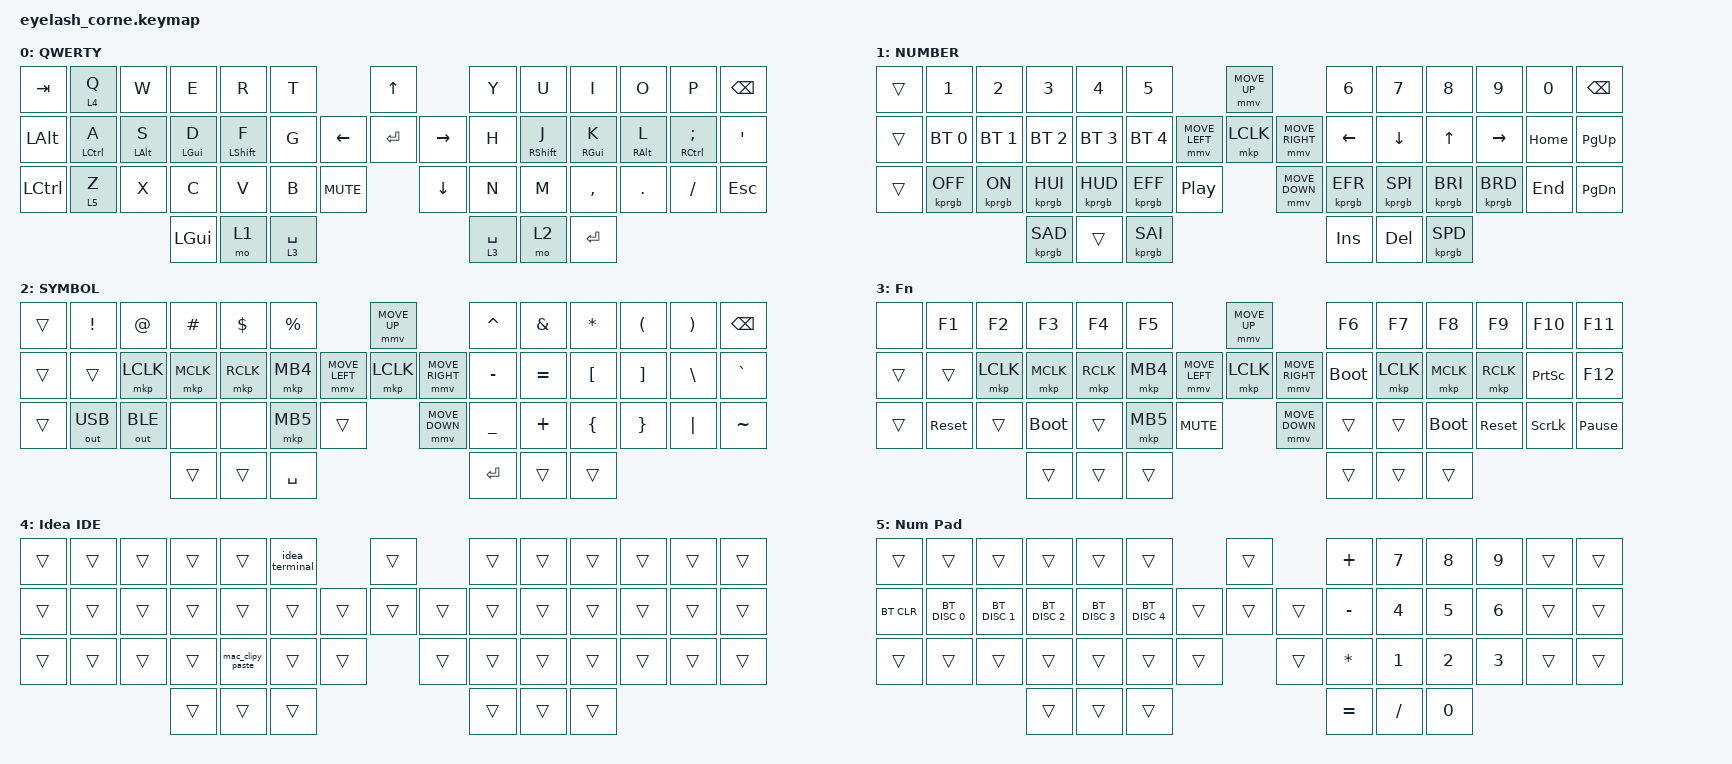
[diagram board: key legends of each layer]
#define ZMK_POINTING_DEFAULT_MOVE_VAL 1200  // 600
#define ZMK_POINTING_DEFAULT_SCRL_VAL 25   // 10

#include <input/processors.dtsi>
#include <zephyr/dt-bindings/input/input-event-codes.h>
#include <behaviors.dtsi>
#include <behaviors/runtime-sensor-rotate.dtsi>
#include <dt-bindings/zmk/bt.h>
#include <dt-bindings/zmk/keys.h>
#include <dt-bindings/zmk/outputs.h>
#include <dt-bindings/zmk/pointing.h>
#include <dt-bindings/zmk/rgb.h>

&soft_off { hold-time-ms = <2000>; };

/ {
    behaviors {
        td0: td0 {
            compatible = "zmk,behavior-tap-dance";
            display-name = "Shift/Caps Lock Tap Dance";
            #binding-cells = <0>;
            bindings = <&kp LEFT_SHIFT>, <&kp CAPS>;
        };

        rsr_vol: rsr_vol {
            compatible = "zmk,behavior-runtime-sensor-rotate";
            #sensor-binding-cells = <0>;
            tap-ms = <5>;
            cw-binding = <&kp C_VOL_UP>;
            ccw-binding = <&kp C_VOL_DN>;
        };

        rsr_trans: rsr_trans {
            compatible = "zmk,behavior-runtime-sensor-rotate";
            #sensor-binding-cells = <0>;
            tap-ms = <0>;
        };

        kprgb: kprgb {
            compatible = "keypaw,behavior-rgb-matrix";
            #binding-cells = <2>;
            initial-effect = <0>;
            // Must be set: the module reads an absent boolean as false (off)
            initial-on;

            // QWERTY stays dark; the layer overlays below do the lighting
            fx_off: fx_off {
                compatible = "keypaw,rgb-matrix-solid";
                #binding-cells = <0>;
                color = <0x000000>;
            };
        };

        hrm_left: hrm_left {
            compatible = "zmk,behavior-hold-tap";
            label = "HRM_LEFT";
            bindings = <&kp>, <&kp>;

            #binding-cells = <2>;
            tapping-term-ms = <150>;
            quick-tap-ms = <140>;
            hold-trigger-key-positions = <1 0 13 28 29 14 15 2 3 4 5 18 33 44 43 42 32 17 16 31 30>;
            hold-trigger-on-release;
            flavor = "tap-preferred";
        };

        hrm_right: hrm_right {
            compatible = "zmk,behavior-hold-tap";
            label = "HRM_RIGHT";
            bindings = <&kp>, <&kp>;

            #binding-cells = <2>;
            hold-trigger-key-positions = <7 8 9 10 11 12 22 23 24 25 26 27 36 37 38 39 40 41 45 46 47>;
            tapping-term-ms = <150>;
            quick-tap-ms = <140>;
            hold-trigger-on-release;
            flavor = "tap-preferred";
        };
    };

    macros {
        lock_mac: lock_mac {
            compatible = "zmk,behavior-macro";
            #binding-cells = <0>;
            bindings =
                <&macro_press>,
                <&kp LCTRL &kp LGUI &kp Q>,
                <&macro_pause_for_release>,
                <&macro_release>,
                <&kp LCTRL &kp LGUI &kp Q>;

            label = "LOCK_MAC";
        };

        screen_shot: screen_shot {
            compatible = "zmk,behavior-macro";
            #binding-cells = <0>;
            bindings =
                <&macro_press>,
                <&kp LCTRL &kp LSHIFT &kp LGUI &kp NUMBER_4>,
                <&macro_pause_for_release>,
                <&macro_release>,
                <&kp LCTRL &kp LSHIFT &kp LGUI &kp NUMBER_4>;

            label = "SCREEN_SHOT";
        };

        launch_pad: launch_pad {
            compatible = "zmk,behavior-macro";
            #binding-cells = <0>;
            bindings =
                <&macro_press>,
                <&kp LGUI &kp SPACE>,
                <&macro_pause_for_release>,
                <&macro_release>,
                <&kp LGUI &kp SPACE>;

            label = "LAUNCH_PAD";
        };

        one_p_vault: one_p_vault {
            compatible = "zmk,behavior-macro";
            #binding-cells = <0>;
            bindings =
                <&macro_press>,
                <&kp LGUI &kp LSHFT &kp SPACE>,
                <&macro_pause_for_release>,
                <&macro_release>,
                <&kp LGUI &kp LSHIFT &kp SPACE>;

            label = "ONE_P_VAULT";
        };

        mac_home: mac_home {
            compatible = "zmk,behavior-macro";
            #binding-cells = <0>;
            bindings =
                <&macro_press>,
                <&kp LGUI &kp LEFT>,
                <&macro_pause_for_release>,
                <&macro_release>,
                <&kp LGUI &kp LEFT_ARROW>;

            label = "MAC_HOME";
        };

        mac_end: mac_end {
            compatible = "zmk,behavior-macro";
            #binding-cells = <0>;
            bindings =
                <&macro_press>,
                <&kp LGUI &kp RIGHT>,
                <&macro_pause_for_release>,
                <&macro_release>,
                <&kp LGUI &kp RIGHT>;

            label = "MAC_END";
        };

        screen_recording: screen_recording {
            compatible = "zmk,behavior-macro";
            #binding-cells = <0>;
            bindings =
                <&macro_press>,
                <&kp LCTRL &kp LSHIFT &kp LGUI &kp N5>,
                <&macro_pause_for_release>,
                <&macro_release>,
                <&kp LCTRL &kp LSHIFT &kp LGUI &kp N5>;

            label = "SCREEN_RECORDING";
        };

        idea_terminal: idea_terminal {
            compatible = "zmk,behavior-macro";
            #binding-cells = <0>;
            bindings =
                <&macro_press>,
                <&kp LALT &kp F12>,
                <&macro_pause_for_release>,
                <&macro_release>,
                <&kp LALT &kp F12>;

            label = "IDEA_TERMINAL";
        };

        mac_clipy_paste: mac_clipy_paste {
            compatible = "zmk,behavior-macro";
            #binding-cells = <0>;
            bindings =
                <&macro_press>,
                <&kp LGUI &kp LS(V)>,
                <&macro_pause_for_release>,
                <&macro_release>,
                <&kp LGUI &kp LS(V)>;

            label = "MAC_CLIPY_PASTE";
        };

        screenshot_whole_screen: screenshot_whole_screen {
            compatible = "zmk,behavior-macro";
            #binding-cells = <0>;
            bindings =
                <&macro_press>,
                <&kp LCTRL &kp LSHIFT &kp LGUI &kp NUMBER_3>,
                <&macro_pause_for_release>,
                <&macro_release>,
                <&kp LCTRL &kp LSHIFT &kp LGUI &kp NUMBER_3>;

            label = "SCREENSHOT_WHOLE_SCREEN";
        };
    };

    combos {
        compatible = "zmk,combos";

        softoff {
            bindings = <&soft_off>;
            key-positions = <1 15 29>;
        };

        one_p_vault {
            bindings = <&one_p_vault>;
            key-positions = <43 46>;
            layers = <0>;
        };

        screen_shot {
            bindings = <&screen_shot>;
            key-positions = <28 41>;
            layers = <0>;
        };

        screen_recording {
            bindings = <&screen_recording>;
            key-positions = <13 27>;
            layers = <0>;
        };

        caps {
            bindings = <&kp CAPSLOCK>;
            key-positions = <8 4>;
            layers = <0>;
        };

        lock_mac {
            bindings = <&lock_mac>;
            key-positions = <0 1 2>;
            layers = <0>;
        };

        clear_bt_profiles {
            bindings = <&bt BT_CLR_ALL>;
            key-positions = <1 2 3 4 8 9 10 11>;
            layers = <0>;
        };

        screenshot_whole_screen {
            bindings = <&screenshot_whole_screen>;
            key-positions = <0 12>;
        };
    };

    rgb_conditions: rgb_conditions {
        compatible = "keypaw,rgb-conditions";

        cond_number: cond_number {
            compatible = "keypaw,rgb-condition-layer";
            layer = <1>;
            only-topmost;
        };

        cond_symbol: cond_symbol {
            compatible = "keypaw,rgb-condition-layer";
            layer = <2>;
            only-topmost;
        };

        cond_fn: cond_fn {
            compatible = "keypaw,rgb-condition-layer";
            layer = <3>;
            only-topmost;
        };

        cond_ide: cond_ide {
            compatible = "keypaw,rgb-condition-layer";
            layer = <4>;
            only-topmost;
        };

        cond_numpad: cond_numpad {
            compatible = "keypaw,rgb-condition-layer";
            layer = <5>;
            only-topmost;
        };
    };

    // Light the keys that have something assigned on the active layer
    rgb_overlays: rgb_overlays {
        compatible = "keypaw,rgb-overlays";

        layer_number: layer_number {
            compatible = "keypaw,rgb-overlay";
            condition = <&cond_number>;
            keys = <1 2 3 4 5 7 8 9 10 11 12 14 15 16 17 18 22 23 24 25 26 27 29 30 31 32 33 36 37 38 39 40 41 42 44 45 46 47>;

            fx_number {
                compatible = "keypaw,rgb-matrix-solid";
                #binding-cells = <0>;
                color = <0x00AAFF>;
            };
        };

        layer_symbol: layer_symbol {
            compatible = "keypaw,rgb-overlay";
            condition = <&cond_symbol>;
            keys = <1 2 3 4 5 7 8 9 10 11 12 15 16 17 18 22 23 24 25 26 27 29 30 33 36 37 38 39 40 41 44 45>;

            fx_symbol {
                compatible = "keypaw,rgb-matrix-solid";
                #binding-cells = <0>;
                color = <0xAA00FF>;
            };
        };

        layer_fn: layer_fn {
            compatible = "keypaw,rgb-overlay";
            condition = <&cond_fn>;
            keys = <1 2 3 4 5 7 8 9 10 11 12 15 16 17 18 22 23 24 25 26 27 29 31 33 38 39 40 41>;

            fx_fn {
                compatible = "keypaw,rgb-matrix-solid";
                #binding-cells = <0>;
                color = <0xFFFFFF>;
            };
        };

        layer_ide: layer_ide {
            compatible = "keypaw,rgb-overlay";
            condition = <&cond_ide>;
            keys = <5 32>;

            fx_ide {
                compatible = "keypaw,rgb-matrix-solid";
                #binding-cells = <0>;
                color = <0xFF8000>;
            };
        };

        layer_numpad: layer_numpad {
            compatible = "keypaw,rgb-overlay";
            condition = <&cond_numpad>;
            keys = <7 8 9 10 22 23 24 25 36 37 38 39 45 46 47>;

            fx_numpad {
                compatible = "keypaw,rgb-matrix-solid";
                #binding-cells = <0>;
                color = <0x00FF40>;
            };
        };

        layer_numpad_bt: layer_numpad_bt {
            compatible = "keypaw,rgb-overlay";
            condition = <&cond_numpad>;
            keys = <14 15 16 17 18>;

            fx_numpad_bt {
                compatible = "keypaw,rgb-matrix-solid";
                #binding-cells = <0>;
                color = <0x0040FF>;
            };
        };

        layer_numpad_bt_clr: layer_numpad_bt_clr {
            compatible = "keypaw,rgb-overlay";
            condition = <&cond_numpad>;
            keys = <13>;

            fx_numpad_bt_clr {
                compatible = "keypaw,rgb-matrix-solid";
                #binding-cells = <0>;
                color = <0xFF0000>;
            };
        };
    };

    keymap {
        compatible = "zmk,keymap";

        default_layer {
            display-name = "QWERTY";
            bindings = <
&kp TAB    &lt 4 Q            &kp W             &kp E             &kp R               &kp T                                &kp UP                &kp Y        &kp U                &kp I              &kp O              &kp P                  &kp BSPC
&kp LALT   &hrm_left LCTRL A  &hrm_left LALT S  &hrm_left LGUI D  &hrm_left LSHIFT F  &kp G                      &kp LEFT  &kp ENTER  &kp RIGHT  &kp H        &hrm_right RSHIFT J  &hrm_right RGUI K  &hrm_right RALT L  &hrm_right RCTRL SEMI  &kp SQT
&kp LCTRL  &lt 5 Z            &kp X             &kp C             &kp V               &kp B        &kp C_MUTE              &kp DOWN              &kp N        &kp M                &kp COMMA          &kp DOT            &kp FSLH               &kp ESC
                                                &kp LGUI          &mo 1               &lt 3 SPACE                                                &lt 3 SPACE  &mo 2                &kp ENTER
            >;

            sensor-bindings = <&inc_dec_kp C_VOLUME_UP C_VOLUME_DOWN>;
        };

        lower_layer {
            display-name = "NUMBER";
            bindings = <
&trans  &kp N1           &kp N2          &kp N3           &kp N4           &kp N5                                               &mmv MOVE_UP                     &kp N6           &kp N7           &kp N8           &kp N9           &kp N0    &kp BSPC
&trans  &bt BT_SEL 0     &bt BT_SEL 1    &bt BT_SEL 2     &bt BT_SEL 3     &bt BT_SEL 4                         &mmv MOVE_LEFT  &mkp LCLK       &mmv MOVE_RIGHT  &kp LEFT         &kp DOWN         &kp UP           &kp RIGHT        &kp HOME  &kp PG_UP
&trans  &kprgb RGB_OFF  &kprgb RGB_ON  &kprgb RGB_HUI  &kprgb RGB_HUD  &kprgb RGB_EFF  &kp C_PLAY_PAUSE                    &mmv MOVE_DOWN                   &kprgb RGB_EFR  &kprgb RGB_SPI  &kprgb RGB_BRI  &kprgb RGB_BRD  &kp END   &kp PG_DN
                                         &kprgb RGB_SAD  &trans           &kprgb RGB_SAI                                                                       &kp INS          &kp DEL          &kprgb RGB_SPD
            >;

            sensor-bindings = <&inc_dec_kp C_NEXT C_PREV>;
        };

        raise_layer {
            display-name = "SYMBOL";
            bindings = <
&trans  &kp EXCL      &kp AT        &kp HASH   &kp DLLR   &kp PRCNT                            &mmv MOVE_UP                     &kp CARET  &kp AMPS   &kp ASTRK  &kp LPAR  &kp RPAR  &kp BSPC
&trans  &trans        &mkp LCLK     &mkp MCLK  &mkp RCLK  &mkp MB4             &mmv MOVE_LEFT  &mkp LCLK       &mmv MOVE_RIGHT  &kp MINUS  &kp EQUAL  &kp LBKT   &kp RBKT  &kp BSLH  &kp GRAVE
&trans  &out OUT_USB  &out OUT_BLE  &none      &none      &mkp MB5   &trans                    &mmv MOVE_DOWN                   &kp UNDER  &kp PLUS   &kp LBRC   &kp RBRC  &kp PIPE  &kp TILDE
                                    &trans     &trans     &kp SPACE                                                             &kp RET    &trans     &trans
            >;

            sensor-bindings = <&rsr_vol &rsr_trans>;
        };

        layer_3 {
            display-name = "Fn";
            bindings = <
&none          &kp F1      &kp F2     &kp F3       &kp F4     &kp F5                                  &mmv MOVE_UP                     &kp F6       &kp F7     &kp F8       &kp F9      &kp F10          &kp F11
&trans          &trans      &mkp LCLK  &mkp MCLK    &mkp RCLK  &mkp MB4                &mmv MOVE_LEFT  &mkp LCLK       &mmv MOVE_RIGHT  &bootloader  &mkp LCLK  &mkp MCLK    &mkp RCLK   &kp PRINTSCREEN  &kp F12
&trans          &sys_reset  &trans     &bootloader  &trans     &mkp MB5  &kp C_MUTE                    &mmv MOVE_DOWN                   &trans       &trans     &bootloader  &sys_reset  &kp SCROLLLOCK   &kp PAUSE_BREAK
                                       &trans       &trans     &trans                                                                   &trans       &trans     &trans
            >;

            sensor-bindings = <&rsr_vol &rsr_trans>;
        };

        layer_4 {
            bindings = <
&trans  &trans  &trans  &trans  &trans            &idea_terminal                    &trans          &trans  &trans  &trans  &trans  &trans  &trans
&trans  &trans  &trans  &trans  &trans            &trans                    &trans  &trans  &trans  &trans  &trans  &trans  &trans  &trans  &trans
&trans  &trans  &trans  &trans  &mac_clipy_paste  &trans          &trans            &trans          &trans  &trans  &trans  &trans  &trans  &trans
                        &trans  &trans            &trans                                            &trans  &trans  &trans
            >;

            label = "Idea IDE";
        };

        layer_5 {
            bindings = <
&trans      &trans         &trans         &trans         &trans         &trans                           &trans          &kp PLUS   &kp N7        &kp N8  &kp N9  &trans  &trans
&bt BT_CLR  &bt BT_DISC 0  &bt BT_DISC 1  &bt BT_DISC 2  &bt BT_DISC 3  &bt BT_DISC 4            &trans  &trans  &trans  &kp MINUS  &kp N4        &kp N5  &kp N6  &trans  &trans
&trans      &trans         &trans         &trans         &trans         &trans         &trans            &trans          &kp ASTRK  &kp NUMBER_1  &kp N2  &kp N3  &trans  &trans
                                          &trans         &trans         &trans                                           &kp EQUAL  &kp FSLH      &kp N0
            >;

            label = "Num Pad";
        };
    };
};
